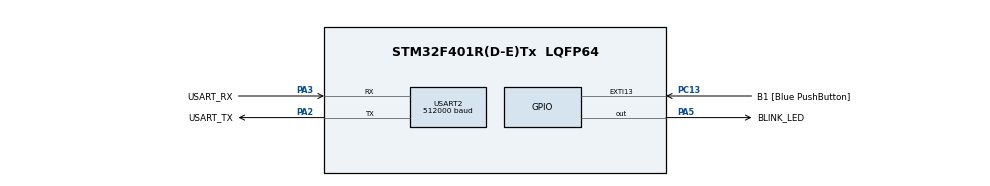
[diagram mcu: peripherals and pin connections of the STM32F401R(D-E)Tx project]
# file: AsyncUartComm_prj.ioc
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Dma.Request0=USART2_TX
Dma.USART2_TX.0.Direction=DMA_MEMORY_TO_PERIPH
Dma.USART2_TX.0.FIFOMode=DMA_FIFOMODE_DISABLE
Dma.USART2_TX.0.Instance=DMA1_Stream6
Dma.USART2_TX.0.MemDataAlignment=DMA_MDATAALIGN_BYTE
Dma.USART2_TX.0.MemInc=DMA_MINC_ENABLE
Dma.USART2_TX.0.Mode=DMA_NORMAL
Dma.USART2_TX.0.PeriphDataAlignment=DMA_PDATAALIGN_BYTE
Dma.USART2_TX.0.PeriphInc=DMA_PINC_DISABLE
Dma.USART2_TX.0.Priority=DMA_PRIORITY_LOW
Mcu.Family=STM32F4
Mcu.Name=STM32F401R(D-E)Tx
Mcu.Package=LQFP64
NVIC.DMA1_Stream6_IRQn=true\:0\:0\:false\:false\:true\:false\:true
NVIC.PriorityGroup=NVIC_PRIORITYGROUP_0
NVIC.TIM1_TRG_COM_TIM11_IRQn=true\:0\:0\:false\:false\:true\:true\:true
NVIC.USART2_IRQn=true\:0\:0\:false\:false\:true\:true\:true
PA13.GPIO_Label=TMS
PA13.Mode=Serial_Wire
PA13.Signal=SYS_JTMS-SWDIO
PA14.GPIO_Label=TCK
PA14.Mode=Serial_Wire
PA14.Signal=SYS_JTCK-SWCLK
PA2.GPIO_Label=USART_TX
PA2.GPIO_Mode=GPIO_MODE_AF_PP
PA2.GPIO_PuPd=GPIO_NOPULL
PA2.GPIO_Speed=GPIO_SPEED_FREQ_LOW
PA2.Mode=Asynchronous
PA2.Signal=USART2_TX
PA3.GPIO_Label=USART_RX
PA3.GPIO_Mode=GPIO_MODE_AF_PP
PA3.GPIO_PuPd=GPIO_NOPULL
PA3.GPIO_Speed=GPIO_SPEED_FREQ_LOW
PA3.Mode=Asynchronous
PA3.Signal=USART2_RX
PA5.GPIO_Label=BLINK_LED
PA5.GPIO_Mode=GPIO_MODE_OUTPUT_PP
PA5.GPIO_PuPd=GPIO_NOPULL
PA5.GPIO_Speed=GPIO_SPEED_FREQ_LOW
PA5.Signal=GPIO_Output
PB3.GPIO_Label=SWO
PB3.Signal=SYS_JTDO-SWO
PC13-ANTI_TAMP.GPIO_Label=B1 [Blue PushButton]
PC13-ANTI_TAMP.GPIO_ModeDefaultEXTI=GPIO_MODE_IT_FALLING
PC13-ANTI_TAMP.GPIO_PuPd=GPIO_NOPULL
PC13-ANTI_TAMP.Signal=GPXTI13
PC14-OSC32_IN.Mode=LSE-External-Oscillator
PC14-OSC32_IN.Signal=RCC_OSC32_IN
PC15-OSC32_OUT.Mode=LSE-External-Oscillator
PC15-OSC32_OUT.Signal=RCC_OSC32_OUT
PH0\ -\ OSC_IN.Mode=HSE-External-Clock-Source
PH0\ -\ OSC_IN.Signal=RCC_OSC_IN
PH1\ -\ OSC_OUT.Mode=HSE-External-Clock-Source
PH1\ -\ OSC_OUT.Signal=RCC_OSC_OUT
ProjectManager.HeapSize=0x200
ProjectManager.StackSize=0x400
ProjectManager.TargetToolchain=STM32CubeIDE
RCC.48MHZClocksFreq_Value=48000000
RCC.AHBFreq_Value=84000000
RCC.APB1CLKDivider=RCC_HCLK_DIV2
RCC.APB1Freq_Value=42000000
RCC.APB1TimFreq_Value=84000000
RCC.APB2Freq_Value=84000000
RCC.APB2TimFreq_Value=84000000
RCC.CortexFreq_Value=84000000
RCC.HCLKFreq_Value=84000000
RCC.HSE_VALUE=8000000
RCC.HSI_VALUE=16000000
RCC.PLLN=336
RCC.PLLP=RCC_PLLP_DIV4
RCC.PLLQ=7
RCC.SYSCLKFreq_VALUE=84000000
RCC.SYSCLKSource=RCC_SYSCLKSOURCE_PLLCLK
RCC.VCOOutputFreq_Value=336000000
TIM11.AutoReloadPreload=TIM_AUTORELOAD_PRELOAD_ENABLE
TIM11.Period=999
TIM11.Prescaler=83
USART2.BaudRate=512000
USART2.VirtualMode=VM_ASYNC
VP_TIM11_VS_ClockSourceINT.Mode=Enable_Timer
board=NUCLEO-F401RE

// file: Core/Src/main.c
/* USER CODE BEGIN Header */
/**
  ******************************************************************************
  * @file           : main.c
  * @brief          : Main program body
  ******************************************************************************
  * @attention
  *
  * <h2><center>&copy; Copyright (c) 2021 STMicroelectronics.
  * All rights reserved.</center></h2>
  *
  * This software component is licensed by ST under BSD 3-Clause license,
  * the "License"; You may not use this file except in compliance with the
  * License. You may obtain a copy of the License at:
  *                        opensource.org/licenses/BSD-3-Clause
  *
  ******************************************************************************
  */
/* USER CODE END Header */
#include "main.h"
#include "dma.h"
#include "tim.h"
#include "usart.h"
#include "gpio.h"

void SystemClock_Config(void);

int main(void)
{

  /* MCU Configuration--------------------------------------------------------*/

  /* Reset of all peripherals, Initializes the Flash interface and the Systick. */

  LL_APB2_GRP1_EnableClock(LL_APB2_GRP1_PERIPH_SYSCFG);
  LL_APB1_GRP1_EnableClock(LL_APB1_GRP1_PERIPH_PWR);

  NVIC_SetPriorityGrouping(NVIC_PRIORITYGROUP_0);

  /* System interrupt init*/

  /* Configure the system clock */
  SystemClock_Config();

  /* Initialize all configured peripherals */
  MX_GPIO_Init();
  MX_DMA_Init();
  MX_USART2_UART_Init();
  MX_TIM11_Init();
  /* USER CODE BEGIN 2 */
  initASC();
  initDEMO();
  BlinkInit();
  LTOS_run();
  /* USER CODE END 2 */

  /* Infinite loop */
  while (1)
  {

  }
}

void SystemClock_Config(void)
{
  LL_FLASH_SetLatency(LL_FLASH_LATENCY_2);
  while(LL_FLASH_GetLatency()!= LL_FLASH_LATENCY_2)
  {
  }
  LL_PWR_SetRegulVoltageScaling(LL_PWR_REGU_VOLTAGE_SCALE2);
  LL_RCC_HSI_SetCalibTrimming(16);
  LL_RCC_HSI_Enable();

   /* Wait till HSI is ready */
  while(LL_RCC_HSI_IsReady() != 1)
  {

  }
  LL_RCC_PLL_ConfigDomain_SYS(LL_RCC_PLLSOURCE_HSI, LL_RCC_PLLM_DIV_16, 336, LL_RCC_PLLP_DIV_4);
  LL_RCC_PLL_Enable();

   /* Wait till PLL is ready */
  while(LL_RCC_PLL_IsReady() != 1)
  {

  }
  LL_RCC_SetAHBPrescaler(LL_RCC_SYSCLK_DIV_1);
  LL_RCC_SetAPB1Prescaler(LL_RCC_APB1_DIV_2);
  LL_RCC_SetAPB2Prescaler(LL_RCC_APB2_DIV_1);
  LL_RCC_SetSysClkSource(LL_RCC_SYS_CLKSOURCE_PLL);

   /* Wait till System clock is ready */
  while(LL_RCC_GetSysClkSource() != LL_RCC_SYS_CLKSOURCE_STATUS_PLL)
  {

  }
  LL_Init1msTick(84000000);
  LL_SetSystemCoreClock(84000000);
  LL_RCC_SetTIMPrescaler(LL_RCC_TIM_PRESCALER_TWICE);
}

void Error_Handler(void)
{
  __disable_irq();
  while (1)
  {
  }
}

/************************ (C) COPYRIGHT STMicroelectronics *****END OF FILE****/
